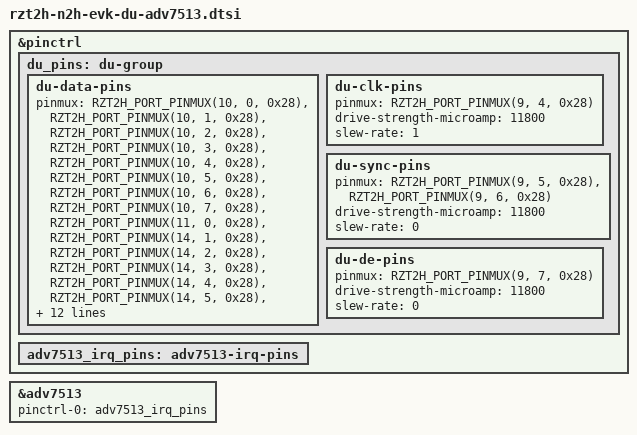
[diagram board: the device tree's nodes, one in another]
// SPDX-License-Identifier: GPL-2.0
/*
 * DT overlay common parts for the RZ/{T2H/N2H} EVKs with ADV7513
 * transmitter connected to DU enabled.
 *
 * Copyright (C) 2026 Renesas Electronics Corp.
 */

#include <dt-bindings/pinctrl/renesas,r9a09g077-pinctrl.h>

#define ADV7513_PARENT_I2C i2c1
#include "rz-smarc-du-adv7513.dtsi"

&pinctrl {
	du_pins: du-group {
		du-data-pins {
			pinmux = <RZT2H_PORT_PINMUX(10, 0, 0x28)>, /* LCDC_DATR0 */
				 <RZT2H_PORT_PINMUX(10, 1, 0x28)>, /* LCDC_DATR1 */
				 <RZT2H_PORT_PINMUX(10, 2, 0x28)>, /* LCDC_DATR2 */
				 <RZT2H_PORT_PINMUX(10, 3, 0x28)>, /* LCDC_DATR3 */
				 <RZT2H_PORT_PINMUX(10, 4, 0x28)>, /* LCDC_DATR4 */
				 <RZT2H_PORT_PINMUX(10, 5, 0x28)>, /* LCDC_DATR5 */
				 <RZT2H_PORT_PINMUX(10, 6, 0x28)>, /* LCDC_DATR6 */
				 <RZT2H_PORT_PINMUX(10, 7, 0x28)>, /* LCDC_DATR7 */
				 <RZT2H_PORT_PINMUX(11, 0, 0x28)>, /* LCDC_DATG0 */
				 <RZT2H_PORT_PINMUX(14, 1, 0x28)>, /* LCDC_DATG1 */
				 <RZT2H_PORT_PINMUX(14, 2, 0x28)>, /* LCDC_DATG2 */
				 <RZT2H_PORT_PINMUX(14, 3, 0x28)>, /* LCDC_DATG3 */
				 <RZT2H_PORT_PINMUX(14, 4, 0x28)>, /* LCDC_DATG4 */
				 <RZT2H_PORT_PINMUX(14, 5, 0x28)>, /* LCDC_DATG5 */
				 <RZT2H_PORT_PINMUX(14, 6, 0x28)>, /* LCDC_DATG6 */
				 <RZT2H_PORT_PINMUX(17, 6, 0x28)>, /* LCDC_DATG7 */
				 <RZT2H_PORT_PINMUX(17, 7, 0x28)>, /* LCDC_DATB0 */
				 <RZT2H_PORT_PINMUX(18, 0, 0x28)>, /* LCDC_DATB1 */
				 <RZT2H_PORT_PINMUX(18, 1, 0x28)>, /* LCDC_DATB2 */
				 <RZT2H_PORT_PINMUX(18, 2, 0x28)>, /* LCDC_DATB3 */
				 <RZT2H_PORT_PINMUX(18, 3, 0x28)>, /* LCDC_DATB4 */
				 <RZT2H_PORT_PINMUX(18, 4, 0x28)>, /* LCDC_DATB5 */
				 <RZT2H_PORT_PINMUX(18, 5, 0x28)>, /* LCDC_DATB6 */
				 <RZT2H_PORT_PINMUX(18, 6, 0x28)>; /* LCDC_DATB7 */
			drive-strength-microamp = <11800>;
			slew-rate = <1>;
		};

		du-clk-pins {
			pinmux = <RZT2H_PORT_PINMUX(9, 4, 0x28)>; /* LCDC_CLK */
			drive-strength-microamp = <11800>;
			slew-rate = <1>;
		};

		du-sync-pins {
			pinmux = <RZT2H_PORT_PINMUX(9, 5, 0x28)>, /* LCDC_HSYNC */
				 <RZT2H_PORT_PINMUX(9, 6, 0x28)>; /* LCDC_VSYNC */
			drive-strength-microamp = <11800>;
			slew-rate = <0>;
		};

		du-de-pins {
			pinmux = <RZT2H_PORT_PINMUX(9, 7, 0x28)>; /* LCDC_DE */
			drive-strength-microamp = <11800>;
			slew-rate = <0>;
		};
	};

	adv7513_irq_pins: adv7513-irq-pins {
	};
};

&adv7513 {
	pinctrl-0 = <&adv7513_irq_pins>;
	pinctrl-names = "default";
};
